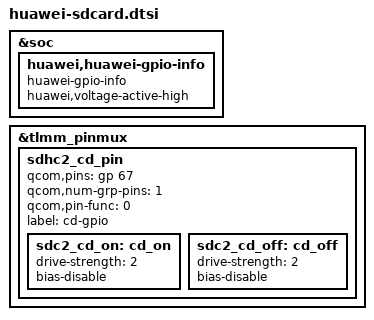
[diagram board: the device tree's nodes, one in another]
&soc {
		huawei,huawei-gpio-info {
			compatible = "huawei-gpio-info";
			huawei,voltage-active-high;
		};
};
&tlmm_pinmux {
	sdhc2_cd_pin {
		qcom,pins = <&gp 67>;
		qcom,num-grp-pins = <1>;
		qcom,pin-func = <0>;
		label = "cd-gpio";
		sdc2_cd_on: cd_on {
			drive-strength = <2>;
			bias-disable;       /* NO PULL */
		};
		sdc2_cd_off: cd_off {
			drive-strength = <2>;
			bias-disable;
		};
	};
};
